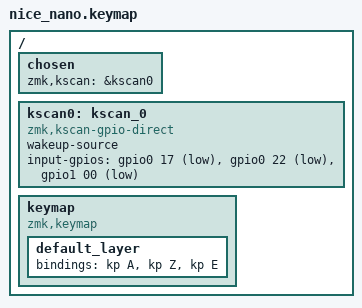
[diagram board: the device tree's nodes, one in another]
#include <behaviors.dtsi>
#include <dt-bindings/zmk/keys.h>

/ {
    chosen {
        zmk,kscan = &kscan0;
    };

    kscan0: kscan_0 {
        compatible = "zmk,kscan-gpio-direct";
        wakeup-source;
        
        input-gpios
            = <&gpio0 17 (GPIO_ACTIVE_LOW | GPIO_PULL_UP)>
            , <&gpio0 22 (GPIO_ACTIVE_LOW | GPIO_PULL_UP)>
            , <&gpio1 00 (GPIO_ACTIVE_LOW | GPIO_PULL_UP)>
            ;
    };

    keymap {
        compatible = "zmk,keymap";

        default_layer {
            bindings = <&kp A &kp Z &kp E>;
        };
    };
};
